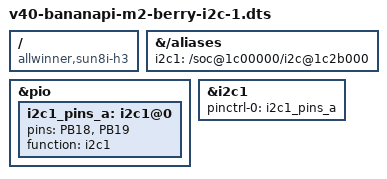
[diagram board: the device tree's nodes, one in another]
/dts-v1/;
/plugin/;

/ {
	compatible = "allwinner,sun8i-h3";

	fragment@0 {
		target-path = "/aliases";
		__overlay__ {
			i2c1 = "/soc@1c00000/i2c@1c2b000";
		};
	};

	fragment@1 {
		target = <&pio>;
		__overlay__ {
			i2c1_pins_a: i2c1@0 {
				pins = "PB18", "PB19";
				function = "i2c1";
			};
		};
	};

	fragment@2 {
		target = <&i2c1>;
		__overlay__ {
			pinctrl-names = "default";
			pinctrl-0 = <&i2c1_pins_a>;
			status = "okay";
		};
	};
};
